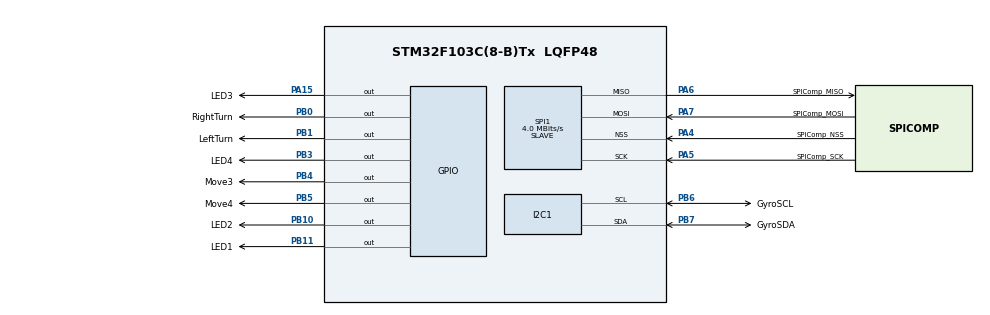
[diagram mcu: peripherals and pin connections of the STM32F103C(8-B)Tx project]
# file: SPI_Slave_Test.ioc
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Mcu.Family=STM32F1
Mcu.Name=STM32F103C(8-B)Tx
Mcu.Package=LQFP48
NVIC.PriorityGroup=NVIC_PRIORITYGROUP_4
NVIC.TIM2_IRQn=true\:0\:0\:false\:false\:true\:false\:true
NVIC.TimeBase=TIM2_IRQn
NVIC.TimeBaseIP=TIM2
PA13.Mode=Serial_Wire
PA13.Signal=SYS_JTMS-SWDIO
PA14.Mode=Serial_Wire
PA14.Signal=SYS_JTCK-SWCLK
PA15.GPIO_Label=LED3
PA15.Signal=GPIO_Output
PA4.GPIO_Label=SPIComp_NSS
PA4.Mode=NSS_Signal_Hard_Input
PA4.Signal=SPI1_NSS
PA5.GPIO_Label=SPIComp_SCK
PA5.Mode=Full_Duplex_Slave
PA5.Signal=SPI1_SCK
PA6.GPIO_Label=SPIComp_MISO
PA6.Mode=Full_Duplex_Slave
PA6.Signal=SPI1_MISO
PA7.GPIO_Label=SPIComp_MOSI
PA7.Mode=Full_Duplex_Slave
PA7.Signal=SPI1_MOSI
PB0.GPIO_Label=RightTurn
PB0.Signal=GPIO_Output
PB1.GPIO_Label=LeftTurn
PB1.Signal=GPIO_Output
PB10.GPIO_Label=LED2
PB10.Signal=GPIO_Output
PB11.GPIO_Label=LED1
PB11.Signal=GPIO_Output
PB3.GPIO_Label=LED4
PB3.Signal=GPIO_Output
PB4.GPIO_Label=Move3
PB4.Signal=GPIO_Output
PB5.GPIO_Label=Move4
PB5.Signal=GPIO_Output
PB6.GPIO_Label=GyroSCL
PB6.Mode=I2C
PB6.Signal=I2C1_SCL
PB7.GPIO_Label=GyroSDA
PB7.Mode=I2C
PB7.Signal=I2C1_SDA
ProjectManager.HeapSize=0x200
ProjectManager.StackSize=0x400
ProjectManager.TargetToolchain=MDK-ARM V5.27
RCC.APB1Freq_Value=8000000
RCC.APB2Freq_Value=8000000
SPI1.CalculateBaudRate=4.0 MBits/s
SPI1.Direction=SPI_DIRECTION_2LINES
SPI1.Mode=SPI_MODE_SLAVE
SPI1.VirtualNSS=VM_NSSHARD
SPI1.VirtualType=VM_SLAVE
VP_SYS_VS_tim2.Mode=TIM2
board=custom

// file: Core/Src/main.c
/* USER CODE BEGIN Header */
/**
  ******************************************************************************
  * @file           : main.c
  * @brief          : Main program body
  ******************************************************************************
  * @attention
  *
  * <h2><center>&copy; Copyright (c) 2020 STMicroelectronics.
  * All rights reserved.</center></h2>
  *
  * This software component is licensed by ST under BSD 3-Clause license,
  * the "License"; You may not use this file except in compliance with the
  * License. You may obtain a copy of the License at:
  *                        opensource.org/licenses/BSD-3-Clause
  *
  ******************************************************************************
  */
/* USER CODE END Header */
#include "main.h"

I2C_HandleTypeDef hi2c1;
SPI_HandleTypeDef hspi1;

/* USER CODE BEGIN PV */
// Global variables for light frequencies
uint8_t lightFreqHz1 = 10;
uint8_t lightFreqHz2 = 12;
uint8_t lightFreqHz3 = 13;
uint8_t lightFreqHz4 = 14;
/* For floating point
float lightFreqHz1 = 1;
float lightFreqHz2 = 2;
float lightFreqHz3 = 3;
float lightFreqHz4 = 4;
*/

// Initialize buffer variables to store SPI received data
uint8_t instrReceiv;
uint8_t LEDinfo[4];

// Global delay variable for pulse length of move command [ms]
uint32_t movePulseDelay = 5;

// Surface SPI User Made Instructions (even parity)
//1. Write the LED frequencies
const uint8_t WriteLEDFreq_instr = 0x55;
//2. Assert a movement command, read if movement was successfull
const uint8_t AssertLeft_instr = 0x65;
const uint8_t AssertRight_instr = 0x66;
const uint8_t AssertMove3_instr = 0x69;
const uint8_t AssertMove4_instr = 0x6A;
//3. Commands send by MCU to indicate if movement was sent to wheelchair
const uint8_t AckYes = 0x95;
const uint8_t AckNo = 0x96;
/* USER CODE END PV */

void SystemClock_Config(void);
static void MX_GPIO_Init(void);
static void MX_I2C1_Init(void);
static void MX_SPI1_Init(void);

int main(void)
{

  /* MCU Configuration--------------------------------------------------------*/

  /* Reset of all peripherals, Initializes the Flash interface and the Systick. */
  HAL_Init();

  /* Configure the system clock */
  SystemClock_Config();

  /* Initialize all configured peripherals */
  MX_GPIO_Init();
  MX_I2C1_Init();
  MX_SPI1_Init();

  /* Infinite loop */
  while (1)
  {
    // Wait to receive instruction
		HAL_SPI_Receive(&hspi1,&instrReceiv,1,HAL_MAX_DELAY);

		// Execute response depending on instruction sent
		switch(instrReceiv)
		{
				case AssertLeft_instr:
				/* In future check to see if moving through Gyro, only move
				if chair is stationary, send ackYes or ackNo depending on whether
				the chair moved	*/

				// Transmit that you are initiating the turn
				HAL_SPI_Transmit(&hspi1,(uint8_t *)&AckYes,1,HAL_MAX_DELAY);
				// Toggle the left turn pin on for movePulseDelay
				HAL_GPIO_WritePin(LeftTurn_GPIO_Port,LeftTurn_Pin,GPIO_PIN_SET);
				HAL_Delay(movePulseDelay);
				HAL_GPIO_WritePin(LeftTurn_GPIO_Port,LeftTurn_Pin,GPIO_PIN_RESET);
				break;
			case AssertRight_instr:
				/* In future check to see if moving through Gyro, only move
				if chair is stationary, send ackYes or ackNo depending on whether
				the chair moved	*/

				// Transmit that you are initiating the turn
				HAL_SPI_Transmit(&hspi1,(uint8_t *)&AckNo,1,HAL_MAX_DELAY);
				// Toggle the left turn pin on for movePulseDelay
				HAL_GPIO_WritePin(RightTurn_GPIO_Port,RightTurn_Pin,GPIO_PIN_SET);
				HAL_Delay(movePulseDelay);
				HAL_GPIO_WritePin(RightTurn_GPIO_Port,RightTurn_Pin,GPIO_PIN_RESET);
				break;
			case AssertMove3_instr:
				/* In future check to see if moving through Gyro, only move
				if chair is stationary, send ackYes or ackNo depending on whether
				the chair moved	*/

				// Transmit that you are initiating the movement
				HAL_SPI_Transmit(&hspi1,(uint8_t *)&AckYes,1,HAL_MAX_DELAY);
				// Toggle the left turn pin on for movePulseDelay
				HAL_GPIO_WritePin(Move3_GPIO_Port,Move3_Pin,GPIO_PIN_SET);
				HAL_Delay(movePulseDelay);
				HAL_GPIO_WritePin(Move3_GPIO_Port,Move3_Pin,GPIO_PIN_RESET);
				break;
			case AssertMove4_instr:
				/* In future check to see if moving through Gyro, only move
				if chair is stationary, send ackYes or ackNo depending on whether
				the chair moved	*/

				// Transmit that you are initiating the movement
				HAL_SPI_Transmit(&hspi1,(uint8_t *)&AckYes,1,HAL_MAX_DELAY);
				// Toggle the left turn pin on for movePulseDelay
				HAL_GPIO_WritePin(Move4_GPIO_Port,Move4_Pin,GPIO_PIN_SET);
				HAL_Delay(movePulseDelay);
				HAL_GPIO_WritePin(Move4_GPIO_Port,Move4_Pin,GPIO_PIN_RESET);
				break;
			case WriteLEDFreq_instr:
				// Read the incoming data and update light frequency values
				HAL_SPI_Receive(&hspi1,LEDinfo,4,HAL_MAX_DELAY);
				lightFreqHz1 = LEDinfo[0];
				lightFreqHz2 = LEDinfo[1];
				lightFreqHz3 = LEDinfo[2];
				lightFreqHz4 = LEDinfo[3];
				break;
		}
  }
}

void SystemClock_Config(void)
{
  RCC_OscInitTypeDef RCC_OscInitStruct = {0};
  RCC_ClkInitTypeDef RCC_ClkInitStruct = {0};

  /** Initializes the RCC Oscillators according to the specified parameters
  * in the RCC_OscInitTypeDef structure.
  */
  RCC_OscInitStruct.OscillatorType = RCC_OSCILLATORTYPE_HSI;
  RCC_OscInitStruct.HSIState = RCC_HSI_ON;
  RCC_OscInitStruct.HSICalibrationValue = RCC_HSICALIBRATION_DEFAULT;
  RCC_OscInitStruct.PLL.PLLState = RCC_PLL_NONE;
  if (HAL_RCC_OscConfig(&RCC_OscInitStruct) != HAL_OK)
  {
    Error_Handler();
  }
  /** Initializes the CPU, AHB and APB buses clocks
  */
  RCC_ClkInitStruct.ClockType = RCC_CLOCKTYPE_HCLK|RCC_CLOCKTYPE_SYSCLK
                              |RCC_CLOCKTYPE_PCLK1|RCC_CLOCKTYPE_PCLK2;
  RCC_ClkInitStruct.SYSCLKSource = RCC_SYSCLKSOURCE_HSI;
  RCC_ClkInitStruct.AHBCLKDivider = RCC_SYSCLK_DIV1;
  RCC_ClkInitStruct.APB1CLKDivider = RCC_HCLK_DIV1;
  RCC_ClkInitStruct.APB2CLKDivider = RCC_HCLK_DIV1;

  if (HAL_RCC_ClockConfig(&RCC_ClkInitStruct, FLASH_LATENCY_0) != HAL_OK)
  {
    Error_Handler();
  }
}

static void MX_I2C1_Init(void)
{

  hi2c1.Instance = I2C1;
  hi2c1.Init.ClockSpeed = 100000;
  hi2c1.Init.DutyCycle = I2C_DUTYCYCLE_2;
  hi2c1.Init.OwnAddress1 = 0;
  hi2c1.Init.AddressingMode = I2C_ADDRESSINGMODE_7BIT;
  hi2c1.Init.DualAddressMode = I2C_DUALADDRESS_DISABLE;
  hi2c1.Init.OwnAddress2 = 0;
  hi2c1.Init.GeneralCallMode = I2C_GENERALCALL_DISABLE;
  hi2c1.Init.NoStretchMode = I2C_NOSTRETCH_DISABLE;
  if (HAL_I2C_Init(&hi2c1) != HAL_OK)
  {
    Error_Handler();
  }

}

static void MX_SPI1_Init(void)
{

  /* SPI1 parameter configuration*/
  hspi1.Instance = SPI1;
  hspi1.Init.Mode = SPI_MODE_SLAVE;
  hspi1.Init.Direction = SPI_DIRECTION_2LINES;
  hspi1.Init.DataSize = SPI_DATASIZE_8BIT;
  hspi1.Init.CLKPolarity = SPI_POLARITY_LOW;
  hspi1.Init.CLKPhase = SPI_PHASE_1EDGE;
  hspi1.Init.NSS = SPI_NSS_HARD_INPUT;
  hspi1.Init.BaudRatePrescaler = SPI_BAUDRATEPRESCALER_2;
  hspi1.Init.FirstBit = SPI_FIRSTBIT_MSB;
  hspi1.Init.TIMode = SPI_TIMODE_DISABLE;
  hspi1.Init.CRCCalculation = SPI_CRCCALCULATION_DISABLE;
  hspi1.Init.CRCPolynomial = 10;
  if (HAL_SPI_Init(&hspi1) != HAL_OK)
  {
    Error_Handler();
  }

}

static void MX_GPIO_Init(void)
{
  GPIO_InitTypeDef GPIO_InitStruct = {0};

  /* GPIO Ports Clock Enable */
  __HAL_RCC_GPIOA_CLK_ENABLE();
  __HAL_RCC_GPIOB_CLK_ENABLE();

  /*Configure GPIO pin Output Level */
  HAL_GPIO_WritePin(GPIOB, RightTurn_Pin|LeftTurn_Pin|LED2_Pin|LED1_Pin
                          |LED4_Pin|Move3_Pin|Move4_Pin, GPIO_PIN_RESET);

  /*Configure GPIO pin Output Level */
  HAL_GPIO_WritePin(LED3_GPIO_Port, LED3_Pin, GPIO_PIN_RESET);

  /*Configure GPIO pins : RightTurn_Pin LeftTurn_Pin LED2_Pin LED1_Pin
                           LED4_Pin Move3_Pin Move4_Pin */
  GPIO_InitStruct.Pin = RightTurn_Pin|LeftTurn_Pin|LED2_Pin|LED1_Pin
                          |LED4_Pin|Move3_Pin|Move4_Pin;
  GPIO_InitStruct.Mode = GPIO_MODE_OUTPUT_PP;
  GPIO_InitStruct.Pull = GPIO_NOPULL;
  GPIO_InitStruct.Speed = GPIO_SPEED_FREQ_LOW;
  HAL_GPIO_Init(GPIOB, &GPIO_InitStruct);

  /*Configure GPIO pin : LED3_Pin */
  GPIO_InitStruct.Pin = LED3_Pin;
  GPIO_InitStruct.Mode = GPIO_MODE_OUTPUT_PP;
  GPIO_InitStruct.Pull = GPIO_NOPULL;
  GPIO_InitStruct.Speed = GPIO_SPEED_FREQ_LOW;
  HAL_GPIO_Init(LED3_GPIO_Port, &GPIO_InitStruct);

}

void HAL_TIM_PeriodElapsedCallback(TIM_HandleTypeDef *htim)
{
  if (htim->Instance == TIM2) {
    HAL_IncTick();
  }
}

void Error_Handler(void)
{
}

/************************ (C) COPYRIGHT STMicroelectronics *****END OF FILE****/
